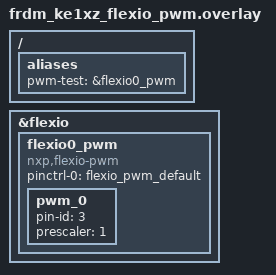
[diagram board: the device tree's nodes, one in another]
/*
 * Copyright 2024 NXP
 *
 * SPDX-License-Identifier: Apache-2.0
 */

/ {
	aliases {
		pwm-test = &flexio0_pwm;
	};
};

&flexio {
	status = "okay";

	flexio0_pwm: flexio0_pwm {
		compatible = "nxp,flexio-pwm";
		#pwm-cells = <3>;
		pinctrl-0 = <&flexio_pwm_default>;
		pinctrl-names = "default";
		status = "okay";

		pwm_0 {
			pin-id = <3>;
			prescaler = <1>;
		};
	};
};
